# ANA_REGS register map
Vendor: Texas Instruments
Peripheral module from a debugger description file (folder cc2538).
Registers are 32-bit, access per field, no defined reset value unless marked. A register's access mark holds for its fields unless they carry their own. Offsets are as the file gives them; lines under a group give offsets from that group; [hi:lo] are bit positions; {n}, {i} and the like mark numbered series; 'fields as' and 'values as' point back to an identical list; <NAME> marks a mode.

## ANA_REGS — Register fields should be considered static unless otherwise noted as dynamic.
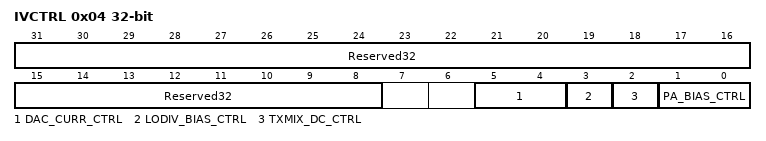
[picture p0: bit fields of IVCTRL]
0x04 IVCTRL — Analog control register
  [31:8] Reserved32 rw — This register is 8 bits in a 32-bit address space.
  [5:4] DAC_CURR_CTRL rw — Controls bias current to DAC 00: 100% IVREF, 0% IREF bias 01: 60% IVREF, 40% IREF bias 10: 40% IVREF, 60% IREF bias 11: 0% IVREF, 100% IREF bias
  [3] LODIV_BIAS_CTRL rw — Controls bias current to LODIV 1: PTAT bias 0: IVREF bias
  [2] TXMIX_DC_CTRL rw — Controls DC bias in TXMIX
  [1:0] PA_BIAS_CTRL rw — Controls bias current to PA 00: IREF bias 01: IREF and IVREF bias (CC2530 mode) 10: PTAT bias 11: Increased PTAT slope bias
